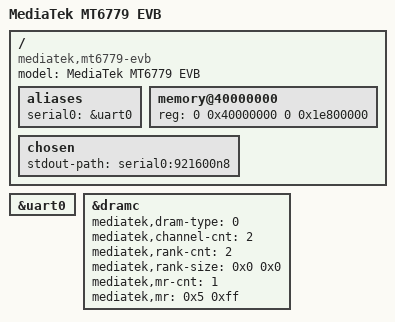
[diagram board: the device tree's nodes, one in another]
// SPDX-License-Identifier: GPL-2.0+
/*
 * Copyright (c) 2019 MediaTek Inc.
 * Author: Mars.C <mars.cheng@mediatek.com>
 *
 */

/dts-v1/;
#include "mt6779.dtsi"

/ {
	model = "MediaTek MT6779 EVB";
	compatible = "mediatek,mt6779-evb", "mediatek,mt6779";

	aliases {
		serial0 = &uart0;
	};

	memory@40000000 {
		device_type = "memory";
		reg = <0 0x40000000 0 0x1e800000>;
	};

	chosen {
		stdout-path = "serial0:921600n8";
	};
};

&uart0 {
	status = "okay";
};

&dramc {
	mediatek,dram-type = <0>;
	mediatek,channel-cnt = <2>;
	mediatek,rank-cnt = <2>;
	mediatek,rank-size = <0x0 0x0>;
	mediatek,mr-cnt = <1>;
	mediatek,mr = <0x5 0xff>;
};
